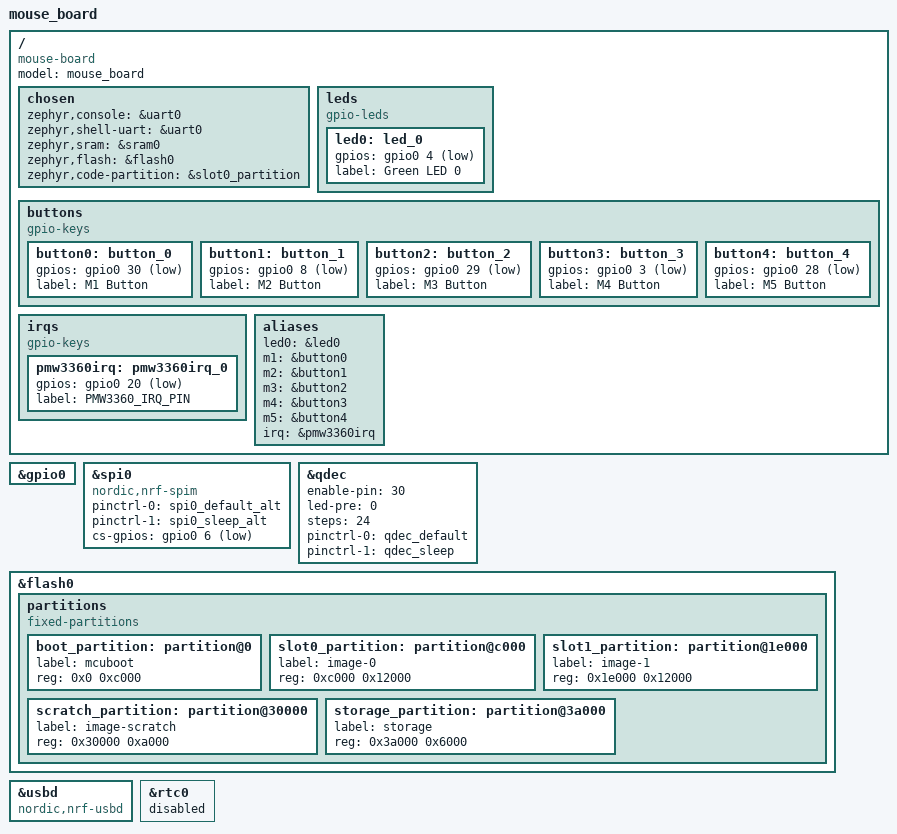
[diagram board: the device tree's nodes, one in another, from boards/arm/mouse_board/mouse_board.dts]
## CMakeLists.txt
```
# SPDX-License-Identifier: Apache-2.0

cmake_minimum_required(VERSION 3.20.0)

find_package(Zephyr REQUIRED HINTS $ENV{ZEPHYR_BASE})

project(baldr_mouse)

FILE(GLOB APP_SOURCE src/*.c)

target_include_directories(app PRIVATE inc/)
target_sources(app PRIVATE
    ${APP_SOURCE}
)
```

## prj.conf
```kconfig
CONFIG_USB_DEVICE_STACK=y
CONFIG_USB_DEVICE_HID=y
CONFIG_USB_DEVICE_PRODUCT="Baldr Mouse"
CONFIG_DYNAMIC_INTERRUPTS=y
CONFIG_USB_HID_POLL_INTERVAL_MS=1
CONFIG_USB_DEVICE_LOG_LEVEL_ERR=y
```

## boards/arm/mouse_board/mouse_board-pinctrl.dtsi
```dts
/*
 * Copyright (c) 2022 Nordic Semiconductor
 * SPDX-License-Identifier: Apache-2.0
 */

&pinctrl {

	spi0_default_alt: spi0_default_alt {
		group1 {
			psels = <NRF_PSEL(SPIM_SCK, 0, 7)>,
				<NRF_PSEL(SPIM_MISO, 0, 14)>,
				<NRF_PSEL(SPIM_MOSI, 0, 15)>;
		};
	};

	spi0_sleep_alt: spi0_sleep_alt {
		group1 {
			psels = <NRF_PSEL(SPIM_SCK, 0, 7)>,
				<NRF_PSEL(SPIM_MISO, 0, 14)>,
				<NRF_PSEL(SPIM_MOSI, 0, 15)>;
			low-power-enable;
		};
	};
	
	qdec_default: qdec_default {
		group1 {
			psels = <NRF_PSEL(QDEC_A, 0, 0)>,
				<NRF_PSEL(QDEC_B, 0, 1)>;
			bias-pull-up;
		};
	};

	qdec_sleep: qdec_sleep {
		group1 {
			psels = <NRF_PSEL(QDEC_A, 0, 0)>,
				<NRF_PSEL(QDEC_B, 0, 1)>;
			bias-pull-up;
			low-power-enable;
		};
	};
};
```

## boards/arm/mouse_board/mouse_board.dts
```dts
// Copyright (c) 2022 Nordic Semiconductor ASA
// SPDX-License-Identifier: Apache-2.0

/dts-v1/;
#include <nordic/nrf52820_qdaa.dtsi>
#include "mouse_board-pinctrl.dtsi"

/ {
	model = "mouse_board";
	compatible = "mouse-board";

	chosen {
		zephyr,console = &uart0;
		zephyr,shell-uart = &uart0;
		zephyr,sram = &sram0;
		zephyr,flash = &flash0;
		zephyr,code-partition = &slot0_partition;
	};

	leds {
		compatible = "gpio-leds";
		led0: led_0 {
			gpios = <&gpio0 4 GPIO_ACTIVE_LOW>;
			label = "Green LED 0";
		};
	};

	buttons {
		compatible = "gpio-keys";
		button0: button_0 {
			gpios = < &gpio0 30 (GPIO_PULL_UP | GPIO_ACTIVE_LOW)>;
			label = "M1 Button";
		};
		button1: button_1 {
			gpios = < &gpio0 8 (GPIO_PULL_UP | GPIO_ACTIVE_LOW)>;
			label = "M2 Button";
		};
		button2: button_2 {
			gpios = < &gpio0 29 (GPIO_PULL_UP | GPIO_ACTIVE_LOW)>;
			label = "M3 Button";
		};
		button3: button_3 {
			gpios = < &gpio0 3 (GPIO_PULL_UP | GPIO_ACTIVE_LOW)>;
			label = "M4 Button";
		};
		button4: button_4 {
			gpios = < &gpio0 28 (GPIO_PULL_UP | GPIO_ACTIVE_LOW)>;
			label = "M5 Button";
		};
	};
	irqs {
        compatible = "gpio-keys";
        pmw3360irq: pmw3360irq_0 {
            gpios = <&gpio0 20 (GPIO_ACTIVE_LOW | GPIO_PULL_UP)>;
            label = "PMW3360_IRQ_PIN";
        };
    };

	/* These aliases are provided for compatibility with samples */
	aliases {
		led0 = &led0;
		m1 = &button0;
		m2 = &button1;
		m3 = &button2;
		m4 = &button3;
		m5 = &button4;

        irq = &pmw3360irq;
	};
};

&gpio0 {
	status = "okay";
};

&spi0 {
	compatible = "nordic,nrf-spim";
	status = "okay";
	pinctrl-0 = <&spi0_default_alt>;
	pinctrl-1 = <&spi0_sleep_alt>;
	pinctrl-names = "default", "sleep";
	cs-gpios = <&gpio0 6 GPIO_ACTIVE_LOW>;
};


&qdec {
	status = "okay";
	enable-pin = <30>;
	led-pre = <0>;
	steps = <24>;
	pinctrl-0 = <&qdec_default>;
	pinctrl-1 = <&qdec_sleep>;
	pinctrl-names = "default", "sleep";
};

&flash0 {
	partitions {
		compatible = "fixed-partitions";
		#address-cells = <1>;
		#size-cells = <1>;

		boot_partition: partition@0 {
			label = "mcuboot";
			reg = <0x0 0xc000>;
		};
		slot0_partition: partition@c000 {
			label = "image-0";
			reg = <0xc000 0x12000>;
		};
		slot1_partition: partition@1e000 {
			label = "image-1";
			reg = <0x1e000 0x12000>;
		};
		scratch_partition: partition@30000 {
			label = "image-scratch";
			reg = <0x30000 0xa000>;
		};
		storage_partition: partition@3a000 {
			label = "storage";
			reg = <0x3a000 0x6000>;
		};
	};
};

zephyr_udc0: &usbd {
	compatible = "nordic,nrf-usbd";
	status = "okay";
};

&rtc0 {
	status = "disabled";
};
```

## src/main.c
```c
#include "mouse.h"
#include <zephyr/kernel.h>
#include <zephyr/sys/byteorder.h>
#include <zephyr/logging/log.h>
#include "timing_utils.h"

LOG_MODULE_REGISTER(main, CONFIG_LOG_DEFAULT_LEVEL);

void test_func(void) {
    motion_info_t motion = read_motion();
    // LOG_INF("dx: %i, dy: %i", motion.dx, motion.dy);
}

void main(void) {
    LOG_INF("Starting mouse");
    // init_pmw3360_sensor();
    // while(!is_pmw3360_ready()){
    //     k_sleep(K_MSEC(1));
    // }
    init_mouse();
    LOG_INF("Mouse Initialized");

    // uint32_t time = 0;
    set_wireless(true);
    k_sleep(K_MSEC(1000));
    for (;;) {
        // time = measure_function_time(test_func);
        // LOG_INF("Time taken by function: %u microseconds", time);
        // k_sleep(K_MSEC(100));
        handle_mouse_transmission();
    }
}
```

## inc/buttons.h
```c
#ifndef MOUSE_BUTTONS_H
#define MOUSE_BUTTONS_H

#include <zephyr/kernel.h>
#include <zephyr/device.h>
#include <zephyr/drivers/gpio.h>

#include "hw_config.h"

#define DEBOUNCE_COUNT 5

bool init_buttons(void);

int button_debounce(void);

static void configure_callback(const struct gpio_dt_spec *spec, gpio_callback_handler_t handler, struct gpio_callback *cb);

void button_callback(const struct device *dev, struct gpio_callback *cb, uint32_t pins);

void fetch_buttons(uint8_t* button_array);
void get_state(uint8_t *states);

#endif // MOUSE_BUTTONS_H
```

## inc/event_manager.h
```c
#ifndef MOUSE_EVENT_MANGER_H
#define MOUSE_EVENT_MANGER_H

#include <zephyr/kernel.h>
#include <zephyr/sys/sem.h>
#include <zephyr/spinlock.h>
#include "hid.h"
#include "event_types.h"

#define NUM_EVENTS 10
#define EVENT_MANAGER_STACK_SIZE 1024 // bytes


typedef struct {
    event_t events[NUM_EVENTS];
    uint8_t head;
    uint8_t tail;
    uint8_t count;
    struct k_sem sem;
    struct k_spinlock lock;
} event_queue_t;

typedef struct {
    event_queue_t event_queue;
    struct k_spinlock queue_lock;
    struct k_sem event_sem;
    k_tid_t event_manager_tid;
    struct k_thread thread;
} event_manager_t;

void init_event_queue(event_queue_t* event_queue);

void create_event(event_t* event, event_type_t type, const void* data, size_t size);

event_t create_motion_event(motion_event_t* motion_event);

event_t create_hid_event(hid_event_t* hid_event);

void enqueue_event(event_queue_t* event_queue, event_t event);

event_t *dequeue_event(event_queue_t* event_queue);

bool is_event_queue_empty(event_queue_t* event_queue);

bool is_event_queue_full(event_queue_t* event_queue);

void init_event_manager(event_manager_t* event_manager, hid_t* hid);

void start_event_manager(event_manager_t* event_manager);

void stop_event_manager(event_manager_t* event_manager);

void event_manager_thread(void* arg1, void* arg2, void* arg3);

void motion_event_handler(motion_event_t* event);


#endif // MOUSE_EVENT_MANGER_H
```

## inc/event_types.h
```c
#ifndef MOUSE_EVENT_TYPES_H
#define MOUSE_EVENT_TYPES_H

#include <zephyr/kernel.h>
#include "hid_config.h"

typedef enum {
    MOTION_EVENT,
    BUTTON_EVENT,
    WHEEL_EVENT,
    HID_EVENT,
    INVALID_EVENT
} event_type_t;

typedef struct {
    event_type_t type;
    void *data;
    size_t data_size;
} event_t;

typedef struct {
    event_type_t type;
    int16_t dx;
    int16_t dy;
} motion_event_t;


typedef struct {
    event_type_t type;
    uint8_t button_num;
} button_event_t;

typedef struct {
    event_type_t type;
    int16_t motion;
} wheel_event_t;

typedef struct {
    event_type_t type;
    uint8_t message[REPORT_SIZE];
}  hid_event_t;


#endif //MOUSE_EVENT_TYPES_H
```

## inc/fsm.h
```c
#ifndef MOUSE_FSM_H
#define MOUSE_FSM_H

#include <zephyr/kernel.h>
// #include "buttons.h"

// States will be defined a byte to save space

#define INIT_MODE           0
#define SEARCHING_MODE      1
#define USB_MODE            2
#define WIRELESS_MODE       3

typedef struct {
    uint8_t state;
    uint8_t prev_state;

    uint8_t message[5];
} FSM_Data;

void run_fsm(FSM_Data *fsm_data);

void enter_state(FSM_Data *fsm_data, uint8_t state);


#endif // MOUSE_FSM_H
```

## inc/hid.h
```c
#ifndef MOUSE_HID_H
#define MOUSE_HID_H

#include <zephyr/kernel.h>
#include "hw_config.h"
#include "hid_config.h"
#include "event_types.h"
#include "event_manager.h"
#include <zephyr/sys/slist.h>
#include <zephyr/sys/byteorder.h>
// #include "usb.h"

#define HID_REPORT_QUEUE_SIZE 16
#define MAX_DATA_SIZE 32
#define HID_STACK_SIZE 1024 // bytes

typedef struct {
    uint8_t data[MAX_DATA_SIZE];
    size_t size;
} hid_report_t;

typedef struct {
    hid_report_t reports[HID_REPORT_QUEUE_SIZE];
    uint8_t head;
    uint8_t tail;
    uint8_t count;
    struct k_sem sem;
} hid_report_queue_t;

typedef struct {
    hid_report_queue_t queue;
    struct k_thread thread;
    k_tid_t tid;
    uint16_t report_interval_hz;
} hid_t;


void init_hid(hid_t* hid);

void init_hid_report_queue(hid_report_queue_t* queue);

bool is_queue_full(hid_report_queue_t* queue);

bool is_queue_empty(hid_report_queue_t* queue);

void enqueue_hid_report(hid_report_queue_t* queue, hid_report_t* report);

hid_report_t* dequeue_hid_report(hid_report_queue_t* queue);

void send_hid_report(hid_t* hid, hid_report_t* report);

hid_report_t generate_motion_report(motion_event_t* event);

void hid_thread(void* arg1, void* arg2, void* arg3);

#endif // MOUSE_HID_H
```

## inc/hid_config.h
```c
#ifndef MOUSE_HID_CONFIG
#define MOUSE_HID_CONFIG

#include <zephyr/kernel.h>
#include <zephyr/device.h>
#include <zephyr/drivers/gpio.h>

// Mouse report size
#define REPORT_SIZE                     6 /* 1 byte id + 5 bytes data*/ 

// Usage pages
#define USAGE_PAGE_MOUSE_XY             0x01
#define USAGE_PAGE_MOUSE_WHEEL          0x01
#define USAGE_PAGE_MOUSE_BUTTONS        0x09

// Mouse report ID
#define MOUSE_REPORT_ID             0x01

#define HID_DEVICE_ID               "HID_0"
#define NUM_MOUSE_BUTTONS           5
#define NUM_AXIS                    3 /* X, Y, Mouse Wheel */
#define NUM_ITEMS                   5

#define MOUSE_REPORT_WHEEL_MAX      (0x7F)
#define MOUSE_REPORT_WHEEL_MIN      (-0x7F)

// Mouse axis X and Y max and min values
#define MOUSE_REPORT_XY_MAX         (0x07FF)
#define MOUSE_REPORT_XY_MIN         (-0x07FF)

#define MOUSE_REPORT_BUTTONS_NUM_MAX    8

enum {
    MOUSE_AXIS_X,
    MOUSE_AXIS_Y,
    MOUSE_AXIS_WHEEL,
    MOUSE_AXIS_NUM,
};

// HID report map for a mouse
// For usage pages: https://www.usb.org/sites/default/files/documents/hut1_12v2.pdf
#define REPORT_MAP                                              \
    /* Mouse Report */                                          \
    0x09, 0x01, /* Usage (pointer) */                           \
    0xA1, 0x00, /* Collection (physical)*/                      \
                                                                \
    0x85, MOUSE_REPORT_ID, /* Report ID */                      \
                                                                \
    /* Button Inputs */                                         \
    0x05, USAGE_PAGE_MOUSE_BUTTONS,                             \
    0x19, 0x01,       /* Usage Minimum (1) */                   \
    0x29, 0x08,       /* Usage Maximum (8) */                   \
    0x15, 0x00,       /* Logical Minimum (0) */                 \
    0x25, 0x01,       /* Logical Maximum (1) */                 \
    0x75, 0x01,       /* Report Size (1) */                     \
    0x95, MOUSE_REPORT_BUTTONS_NUM_MAX, /* Report Count */      \
    0x81, 0x02,       /* Input (data, variable, absolute) */    \
                                                                \
    /* Wheel Inputs */                                          \
    0x05, USAGE_PAGE_MOUSE_WHEEL,                               \
    0x09, 0x38,       /* Usage (Wheel) */                       \
    0x15, 0x81,       /* Logical Minimum (-127) */              \
    0x25, 0x7F,       /* Logical Maximum (127) */               \
    0x75, 0x08,       /* Report Size (8) */                     \
    0x95, 0x01,       /* Report Count */                        \
    0x81, 0x06,       /* Input (data, variable, relative) */    \
                                                                \
    /* XY Position Inputs */                                    \
    0x05, USAGE_PAGE_MOUSE_XY,                                  \
    0x09, 0x30,       /* Usage (X) */                           \
    0x09, 0x31,       /* Usage (Y) */                           \
    0x16, 0x01, 0xF8,  /* Logical Maximum (2047) */             \
    0x26, 0xFF, 0x07,  /* Logical Minimum (-2047) */            \
    0x75, 0x0C,       /* Report Size (12) */                    \
    0x95, 0x02,       /* Report Count (2) */                    \
    0x81, 0x06,       /* Input (data, variable, relative) */    \
                                                                \
    0xC0              /* End Collection (Physical) */


// HID report descriptor for a mouse
static const uint8_t hid_report_desc[] = {
    0x05, 0x01, /* Usage Page (Generic Desktop) */ 
    0x09, 0x02, /* Usage (Mouse) */
    0xA1, 0x01, /* Collection (Application)*/
    REPORT_MAP,
    0xC0,
};

#endif // MOUSE_HID_CONFIG
```

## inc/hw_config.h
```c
#ifndef MOUSE_HW_INFO_H
#define MOUSE_HW_INFO_H

#include <zephyr/kernel.h>
#include <zephyr/device.h>
#include <zephyr/drivers/gpio.h>
#include <zephyr/usb/usb_device.h>
#include <zephyr/usb/class/usb_hid.h>

#define GPIO_SPEC(node_id) GPIO_DT_SPEC_GET_OR(node_id, gpios, {0})

#define MOUSE_BUTTON_REPORT_POS     0
#define MOUSE_X_REPORT_POS          1
#define MOUSE_Y_REPORT_POS          2

// Buttons
#define M1_NODE DT_ALIAS(m1)
#define M2_NODE DT_ALIAS(m2)
#define M3_NODE DT_ALIAS(m3)
#define M4_NODE DT_ALIAS(m4)
#define M5_NODE DT_ALIAS(m5)

#define SPI_INSTANCE                        0
#define SPI_NODE                            DT_NODELABEL(spi0)
#define SPI_FREQUENCY                       SPI_FREQUENCY_FREQUENCY_M8
#define SPI_SCK                             7
#define SPI_MISO                            14
#define SPI_MOSI                            15
// #define PMW3360_IRQ_NODE                    DT_ALIAS(irq)
// static const uint8_t hid_report_desc[] = HID_MOUSE_REPORT_DESC(5);

#endif // MOUSE_HW_INFO_H
```

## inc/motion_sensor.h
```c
#ifndef MOUSE_MOTION_SENSOR_H
#define MOUSE_MOTION_SENSOR_H

#include <zephyr/kernel.h>
#include <zephyr/device.h>
#include "pmw3360.h"
// #include <zephyr/drivers/sensor.h>
// #include <sensor/pmw3360.h>

typedef struct {
    int16_t dx;
    int16_t dy;
} motion_info_t;

int init_pmw3360_sensor(void);
bool is_motion_sensor_ready(void);

bool configure_pmw3360(void);

motion_info_t read_motion(void);
void reset_current_motion_info(void);
motion_info_t get_current_motion_info(void);

bool set_cpi(uint16_t cpi);
uint16_t get_cpi(void);

#endif //MOUSE_MOTION_SENSOR_H
```

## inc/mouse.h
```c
#ifndef MOUSE_H
#define MOUSE_H

#include "wheel.h"
#include "motion_sensor.h"
#include "buttons.h"

typedef struct {
    wheel_data_t wheel_data;
    motion_info_t motion_info;
    uint8_t button_states[5];
} mouse_t;

typedef struct {
    uint16_t cpi;
    bool is_wireless;
} mouse_config_t;

typedef struct {
    void *fifo_reserved;
    mouse_t data;
} message_t; 

int init_mouse();
void update_config(void);
void set_wireless(bool wireless);
void update_mouse(mouse_t* mouse);
void send_hid_message(void);
void handle_mouse_transmission(void);

#endif
```

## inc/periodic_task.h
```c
#ifndef MOUSE_PERIODIC_TASK_H
#define MOUSE_PERIODIC_TASK_H

#include <zephyr/kernel.h>

void set_period_us(uint32_t us);

void set_period_ms(uint32_t ms);

void init_task(void (*f)(struct k_timer*));

#endif // MOUSE_PERIODIC_TASK_H
```

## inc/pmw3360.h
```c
#ifndef MOUSE_PWM3360_H
#define MOUSE_PWM3360_H

#include <nrfx_spim.h>
#include <zephyr/kernel.h>
#include <zephyr/device.h>
#include <zephyr/drivers/gpio.h>
#include <zephyr/drivers/sensor.h>

/* Timings defined by spec */
#define T_NCS_SCLK	            1			            /* 120 ns */
#define T_SRX		            (20 - T_NCS_SCLK)	    /* 20 us */
#define T_SCLK_NCS_WR	        (35 - T_NCS_SCLK)	    /* 35 us */
#define T_SWX		            (180 - T_SCLK_NCS_WR)	/* 180 us */
#define T_SRAD		            160			            /* 160 us */
#define T_SRAD_MOTBR	        35			            /* 35 us */
#define T_BEXIT		            1			            /* 500 ns */

/* Timing defined on SROM download burst mode figure */
#define T_BRSEP		            15			            /* 15 us */

/* Sensor registers */
#define PMW3360_REG_PRODUCT_ID			            0x00
#define PMW3360_REG_REVISION_ID			            0x01
#define PMW3360_REG_MOTION			                0x02
#define PMW3360_REG_DELTA_X_L			            0x03
#define PMW3360_REG_DELTA_X_H			            0x04
#define PMW3360_REG_DELTA_Y_L			            0x05
#define PMW3360_REG_DELTA_Y_H			            0x06
#define PMW3360_REG_SQUAL			                0x07
#define PMW3360_REG_RAW_DATA_SUM		            0x08
#define PMW3360_REG_MAXIMUM_RAW_DATA		        0x09
#define PMW3360_REG_MINIMUM_RAW_DATA		        0x0A
#define PMW3360_REG_SHUTTER_LOWER		            0x0B
#define PMW3360_REG_SHUTTER_UPPER		            0x0C
#define PMW3360_REG_CONTROL			                0x0D
#define PMW3360_REG_CONFIG1			                0x0F
#define PMW3360_REG_CONFIG2			                0x10
#define PMW3360_REG_ANGLE_TUNE			            0x11
#define PMW3360_REG_FRAME_CAPTURE		            0x12
#define PMW3360_REG_SROM_ENABLE			            0x13
#define PMW3360_REG_RUN_DOWNSHIFT		            0x14
#define PMW3360_REG_REST1_RATE_LOWER		        0x15
#define PMW3360_REG_REST1_RATE_UPPER		        0x16
#define PMW3360_REG_REST1_DOWNSHIFT		            0x17
#define PMW3360_REG_REST2_RATE_LOWER		        0x18
#define PMW3360_REG_REST2_RATE_UPPER		        0x19
#define PMW3360_REG_REST2_DOWNSHIFT		            0x1A
#define PMW3360_REG_REST3_RATE_LOWER		        0x1B
#define PMW3360_REG_REST3_RATE_UPPER		        0x1C
#define PMW3360_REG_OBSERVATION			            0x24
#define PMW3360_REG_DATA_OUT_LOWER		            0x25
#define PMW3360_REG_DATA_OUT_UPPER		            0x26
#define PMW3360_REG_RAW_DATA_DUMP		            0x29
#define PMW3360_REG_SROM_ID			                0x2A
#define PMW3360_REG_MIN_SQ_RUN			            0x2B
#define PMW3360_REG_RAW_DATA_THRESHOLD		        0x2C
#define PMW3360_REG_CONFIG5			                0x2F
#define PMW3360_REG_POWER_UP_RESET		            0x3A
#define PMW3360_REG_SHUTDOWN			            0x3B
#define PMW3360_REG_INVERSE_PRODUCT_ID		        0x3F
#define PMW3360_REG_LIFTCUTOFF_TUNE3		        0x41
#define PMW3360_REG_ANGLE_SNAP			            0x42
#define PMW3360_REG_LIFTCUTOFF_TUNE1		        0x4A
#define PMW3360_REG_MOTION_BURST		            0x50
#define PMW3360_REG_LIFTCUTOFF_TUNE_TIMEOUT	        0x58
#define PMW3360_REG_LIFTCUTOFF_TUNE_MIN_LENGTH	    0x5A
#define PMW3360_REG_SROM_LOAD_BURST		            0x62
#define PMW3360_REG_LIFT_CONFIG			            0x63
#define PMW3360_REG_RAW_DATA_BURST		            0x64
#define PMW3360_REG_LIFTCUTOFF_TUNE2		        0x65

/* Sensor identification values */
#define PMW3360_PRODUCT_ID			                0x42
#define PMW3360_FIRMWARE_ID			                0x04

/* Max register count readable in a single motion burst */
#define PMW3360_MAX_BURST_SIZE		12

/* Register count used for reading a single motion burst */
#define PMW3360_BURST_SIZE			6

/* Position of X in motion burst data */
#define PMW3360_DX_POS				2
#define PMW3360_DY_POS				4

/* Rest_En position in Config2 register. */
#define PMW3360_REST_EN_POS			5

#define PMW3360_MAX_CPI				12000
#define PMW3360_MIN_CPI				100

#define SPI_WRITE_BIT				BIT(7)

extern const size_t pmw3360_firmware_length;
extern const uint8_t pmw3360_firmware_data[];

enum async_init_step {
	ASYNC_INIT_STEP_POWER_UP,
	ASYNC_INIT_STEP_FW_LOAD_START,
	ASYNC_INIT_STEP_FW_LOAD_CONTINUE,
	ASYNC_INIT_STEP_FW_LOAD_VERIFY,
	ASYNC_INIT_STEP_CONFIGURE,

	ASYNC_INIT_STEP_COUNT
};

typedef struct {
	struct gpio_callback         irq_gpio_cb;
	struct k_spinlock            lock;
	int16_t                      x;
	int16_t                      y;
    sensor_trigger_handler_t     data_ready_handler;
	// struct k_work                trigger_handler_work;
	struct k_work_delayable      init_work;
	enum async_init_step         async_init_step;
	int                          err;
	bool                         ready;
	bool                         last_read_burst;
} pmw3360_data_t;

typedef struct {
	uint32_t cpi;
} pmw3360_config_t;

bool is_pmw3360_ready(void);
int pmw3360_init(void);
int pmw3360_fetch(void);
int set_pmw3360_cpi(uint32_t cpi);
uint32_t get_pmw3360_cpi(void);

int16_t get_pmw3360_dx(void); 
int16_t get_pmw3360_dy(void); 

int update_rest1_sample_time(uint32_t time);
int update_rest2_sample_time(uint32_t time);
int update_rest3_sample_time(uint32_t time);
int pmw3360_enable_rest(bool rest);

#endif /* MOUSE_PWM3360_H */
```

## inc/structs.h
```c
#ifndef MOUSE_STRUCTS_H
#define MOUSE_STRUCTS_H

#include "pmw3360.h"
#include "event_manager.h"
#include "fsm.h"
#include "transmitter.h"
#include "buttons.h"
#include "usb.h"
#include "mouse.h"
#include "hid.h"

/* Global Data Structurs */ 
extern struct k_sem sem;
extern event_manager_t manager;

extern hid_t hid_device;
extern USB_Data usb;
// extern hid_state hid_state;
extern ESB_Data transmitter;
extern MOUSE_Data mouse;
extern pmw3360_device pmw3360_dev;
extern FSM_Data fsm;

#endif // MOUSE_STRUCTS_H
```
